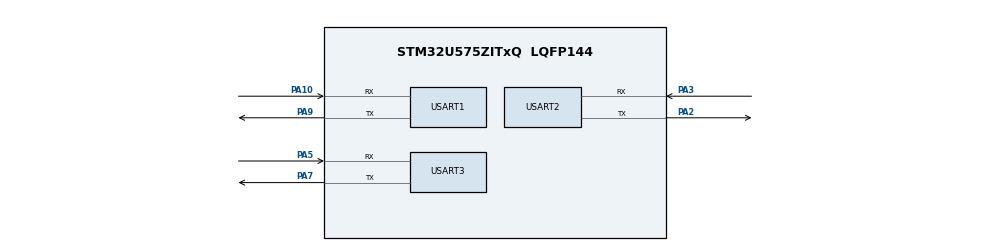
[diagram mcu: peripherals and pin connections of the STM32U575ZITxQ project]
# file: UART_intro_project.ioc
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CORTEX_M33_NS.userName=CORTEX_M33
Mcu.Family=STM32U5
Mcu.Name=STM32U575ZITxQ
Mcu.Package=LQFP144
NUCLEO-U575ZI-Q.LD1=true
NUCLEO-U575ZI-Q.LD2=true
NUCLEO-U575ZI-Q.LD3=true
NUCLEO-U575ZI-Q.VCP=false
NVIC.PriorityGroup=NVIC_PRIORITYGROUP_3
NVIC.USART1_IRQn=true\:0\:0\:false\:false\:true\:true\:true\:true
NVIC.USART2_IRQn=true\:0\:0\:false\:false\:true\:true\:true\:true
NVIC.USART3_IRQn=true\:0\:0\:false\:false\:true\:true\:true\:true
PA10.Mode=Asynchronous
PA10.Signal=USART1_RX
PA2.Mode=Asynchronous
PA2.Signal=USART2_TX
PA3.Mode=Asynchronous
PA3.Signal=USART2_RX
PA5.Mode=Asynchronous
PA5.Signal=USART3_RX
PA7.Mode=Asynchronous
PA7.Signal=USART3_TX
PA9.Mode=Asynchronous
PA9.Signal=USART1_TX
ProjectManager.HeapSize=0x200
ProjectManager.StackSize=0x400
ProjectManager.TargetToolchain=STM32CubeIDE
RCC.ADCFreq_Value=16000000
RCC.DACCLockSelectionVirtual=RCC_DAC1CLKSOURCE_LSI
RCC.EPOD_VALUE=4000000
RCC.HSE_VALUE=16000000
RCC.HSI48_VALUE=48000000
RCC.HSI_VALUE=16000000
RCC.LSE_VALUE=32768
RCC.LSIDIV_VALUE=32000
RCC.MSI_VALUE=4000000
RCC.USBFreq_Value=48000000
RCC.VCOOutputFreq_Value=516000000
USART1.VirtualMode-Asynchronous=VM_ASYNC
USART2.VirtualMode-Asynchronous=VM_ASYNC
USART3.VirtualMode-Asynchronous=VM_ASYNC
VP_LPBAMQUEUE_VS_QUEUE.Mode=QUEUEMODE
VP_LPBAM_VS_SIG1.Mode=SmartRun
VP_LPBAM_VS_SIG4.Mode=LPDMA1
VP_MEMORYMAP_VS_MEMORYMAP.Mode=CurAppReg
VP_NUCLEO-U575ZI-Q_VS_BSP_COMMON.Mode=COMMON
VP_PWR_VS_SECSignals.Mode=Security/Privilege
board=NUCLEO-U575ZI-Q

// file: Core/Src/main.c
/* USER CODE BEGIN Header */
/**
  ******************************************************************************
  * @file           : main.c
  * @brief          : Main program body
  ******************************************************************************
  * @attention
  *
  * Copyright (c) 2026 STMicroelectronics.
  * All rights reserved.
  *
  * This software is licensed under terms that can be found in the LICENSE file
  * in the root directory of this software component.
  * If no LICENSE file comes with this software, it is provided AS-IS.
  *
  ******************************************************************************
  */
/* USER CODE END Header */
#include "main.h"

/* USER CODE BEGIN Includes */
#include "UARTMod.h"

/* USER CODE END Includes */

UART_HandleTypeDef huart1;
UART_HandleTypeDef huart2;
UART_HandleTypeDef huart3;

void SystemClock_Config(void);
static void MX_GPIO_Init(void);
static void MX_USART2_UART_Init(void);
static void MX_USART1_UART_Init(void);
static void MX_USART3_UART_Init(void);

int main(void)
{

  /* MCU Configuration--------------------------------------------------------*/

  /* Reset of all peripherals, Initializes the Flash interface and the Systick. */
  HAL_Init();

  /* Configure the system clock */
  SystemClock_Config();

  /* Initialize all configured peripherals */
  MX_GPIO_Init();
  MX_USART2_UART_Init();
  MX_USART1_UART_Init();
  MX_USART3_UART_Init();
  /* USER CODE BEGIN 2 */

  UARTMod_Init();
  /* USER CODE END 2 */

  /* Initialize leds */
  BSP_LED_Init(LED_GREEN);
  BSP_LED_Init(LED_BLUE);
  BSP_LED_Init(LED_RED);

  /* Infinite loop */
  /* USER CODE BEGIN WHILE */
  while (1) {

	  // 1. Define the test character
//	  uint8_t test_char = 'g';
//
//	  // 2. Transmit 'g' out of USART2 TX
//	  HAL_UART_Transmit(&huart2, &test_char, 1, 100);
//	  // 3. Wait 1 second before sending again to prevent Overrun Errors
//	  HAL_Delay(1000);
//
//	  // 4. Send a different character to test the "off" state
//	  test_char = 'x';
//	  HAL_UART_Transmit(&huart2, &test_char, 1, 100);
//	  HAL_Delay(1000);
    /* USER CODE END WHILE */

  }
}

void SystemClock_Config(void)
{
  RCC_OscInitTypeDef RCC_OscInitStruct = {0};
  RCC_ClkInitTypeDef RCC_ClkInitStruct = {0};

  /** Configure the main internal regulator output voltage
  */
  if (HAL_PWREx_ControlVoltageScaling(PWR_REGULATOR_VOLTAGE_SCALE4) != HAL_OK)
  {
    Error_Handler();
  }

  /** Initializes the CPU, AHB and APB buses clocks
  */
  RCC_OscInitStruct.OscillatorType = RCC_OSCILLATORTYPE_MSI;
  RCC_OscInitStruct.MSIState = RCC_MSI_ON;
  RCC_OscInitStruct.MSICalibrationValue = RCC_MSICALIBRATION_DEFAULT;
  RCC_OscInitStruct.MSIClockRange = RCC_MSIRANGE_4;
  RCC_OscInitStruct.PLL.PLLState = RCC_PLL_NONE;
  if (HAL_RCC_OscConfig(&RCC_OscInitStruct) != HAL_OK)
  {
    Error_Handler();
  }

  /** Initializes the CPU, AHB and APB buses clocks
  */
  RCC_ClkInitStruct.ClockType = RCC_CLOCKTYPE_HCLK|RCC_CLOCKTYPE_SYSCLK
                              |RCC_CLOCKTYPE_PCLK1|RCC_CLOCKTYPE_PCLK2
                              |RCC_CLOCKTYPE_PCLK3;
  RCC_ClkInitStruct.SYSCLKSource = RCC_SYSCLKSOURCE_MSI;
  RCC_ClkInitStruct.AHBCLKDivider = RCC_SYSCLK_DIV1;
  RCC_ClkInitStruct.APB1CLKDivider = RCC_HCLK_DIV1;
  RCC_ClkInitStruct.APB2CLKDivider = RCC_HCLK_DIV1;
  RCC_ClkInitStruct.APB3CLKDivider = RCC_HCLK_DIV1;

  if (HAL_RCC_ClockConfig(&RCC_ClkInitStruct, FLASH_LATENCY_0) != HAL_OK)
  {
    Error_Handler();
  }
}

static void MX_USART1_UART_Init(void)
{

  huart1.Instance = USART1;
  huart1.Init.BaudRate = 115200;
  huart1.Init.WordLength = UART_WORDLENGTH_8B;
  huart1.Init.StopBits = UART_STOPBITS_1;
  huart1.Init.Parity = UART_PARITY_NONE;
  huart1.Init.Mode = UART_MODE_TX_RX;
  huart1.Init.HwFlowCtl = UART_HWCONTROL_NONE;
  huart1.Init.OverSampling = UART_OVERSAMPLING_16;
  huart1.Init.OneBitSampling = UART_ONE_BIT_SAMPLE_DISABLE;
  huart1.Init.ClockPrescaler = UART_PRESCALER_DIV1;
  huart1.AdvancedInit.AdvFeatureInit = UART_ADVFEATURE_NO_INIT;
  if (HAL_UART_Init(&huart1) != HAL_OK)
  {
    Error_Handler();
  }
  if (HAL_UARTEx_SetTxFifoThreshold(&huart1, UART_TXFIFO_THRESHOLD_1_8) != HAL_OK)
  {
    Error_Handler();
  }
  if (HAL_UARTEx_SetRxFifoThreshold(&huart1, UART_RXFIFO_THRESHOLD_1_8) != HAL_OK)
  {
    Error_Handler();
  }
  if (HAL_UARTEx_DisableFifoMode(&huart1) != HAL_OK)
  {
    Error_Handler();
  }

}

static void MX_USART2_UART_Init(void)
{

  huart2.Instance = USART2;
  huart2.Init.BaudRate = 115200;
  huart2.Init.WordLength = UART_WORDLENGTH_8B;
  huart2.Init.StopBits = UART_STOPBITS_1;
  huart2.Init.Parity = UART_PARITY_NONE;
  huart2.Init.Mode = UART_MODE_TX_RX;
  huart2.Init.HwFlowCtl = UART_HWCONTROL_NONE;
  huart2.Init.OverSampling = UART_OVERSAMPLING_16;
  huart2.Init.OneBitSampling = UART_ONE_BIT_SAMPLE_DISABLE;
  huart2.Init.ClockPrescaler = UART_PRESCALER_DIV1;
  huart2.AdvancedInit.AdvFeatureInit = UART_ADVFEATURE_NO_INIT;
  if (HAL_UART_Init(&huart2) != HAL_OK)
  {
    Error_Handler();
  }
  if (HAL_UARTEx_SetTxFifoThreshold(&huart2, UART_TXFIFO_THRESHOLD_1_8) != HAL_OK)
  {
    Error_Handler();
  }
  if (HAL_UARTEx_SetRxFifoThreshold(&huart2, UART_RXFIFO_THRESHOLD_1_8) != HAL_OK)
  {
    Error_Handler();
  }
  if (HAL_UARTEx_DisableFifoMode(&huart2) != HAL_OK)
  {
    Error_Handler();
  }

}

static void MX_USART3_UART_Init(void)
{

  huart3.Instance = USART3;
  huart3.Init.BaudRate = 115200;
  huart3.Init.WordLength = UART_WORDLENGTH_8B;
  huart3.Init.StopBits = UART_STOPBITS_1;
  huart3.Init.Parity = UART_PARITY_NONE;
  huart3.Init.Mode = UART_MODE_TX_RX;
  huart3.Init.HwFlowCtl = UART_HWCONTROL_NONE;
  huart3.Init.OverSampling = UART_OVERSAMPLING_16;
  huart3.Init.OneBitSampling = UART_ONE_BIT_SAMPLE_DISABLE;
  huart3.Init.ClockPrescaler = UART_PRESCALER_DIV1;
  huart3.AdvancedInit.AdvFeatureInit = UART_ADVFEATURE_NO_INIT;
  if (HAL_UART_Init(&huart3) != HAL_OK)
  {
    Error_Handler();
  }
  if (HAL_UARTEx_SetTxFifoThreshold(&huart3, UART_TXFIFO_THRESHOLD_1_8) != HAL_OK)
  {
    Error_Handler();
  }
  if (HAL_UARTEx_SetRxFifoThreshold(&huart3, UART_RXFIFO_THRESHOLD_1_8) != HAL_OK)
  {
    Error_Handler();
  }
  if (HAL_UARTEx_DisableFifoMode(&huart3) != HAL_OK)
  {
    Error_Handler();
  }

}

static void MX_GPIO_Init(void)
{

  /* GPIO Ports Clock Enable */
  __HAL_RCC_GPIOA_CLK_ENABLE();

}

/* USER CODE BEGIN 4 */
void HAL_UART_RxCpltCallback(UART_HandleTypeDef *huart)
{
  /* This catches the hardware interrupt and passes it to your custom file */
  UARTMod_RxCallback(huart);
}
/* USER CODE END 4 */

void Error_Handler(void)
{
  __disable_irq();
  while (1)
  {
  }
}
